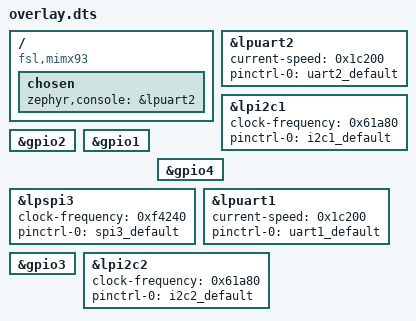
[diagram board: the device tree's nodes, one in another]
/ {
	compatible = "fsl,mimx93";
	chosen {
		zephyr,console = &lpuart2;
	};
};
&lpuart2{
	status = "okay";
	current-speed = < 0x1c200 >;
	pinctrl-0 = < &uart2_default >;
	pinctrl-names = "default";
};
&lpi2c1{
	clock-frequency = < 0x61a80 >;
	pinctrl-0 = < &i2c1_default >;
	pinctrl-names = "default";
};
&gpio2{
	status = "okay";
};
&gpio1{
	status = "okay";
};
&gpio4{
	status = "okay";
};
&lpspi3{
	clock-frequency = < 0xf4240 >;
	pinctrl-0 = < &spi3_default >;
	pinctrl-names = "default";
};
&lpuart1{
	current-speed = < 0x1c200 >;
	pinctrl-0 = < &uart1_default >;
	pinctrl-names = "default";
};
&gpio3{
	status = "okay";
};
&lpi2c2{
	clock-frequency = < 0x61a80 >;
	pinctrl-0 = < &i2c2_default >;
	pinctrl-names = "default";
};
